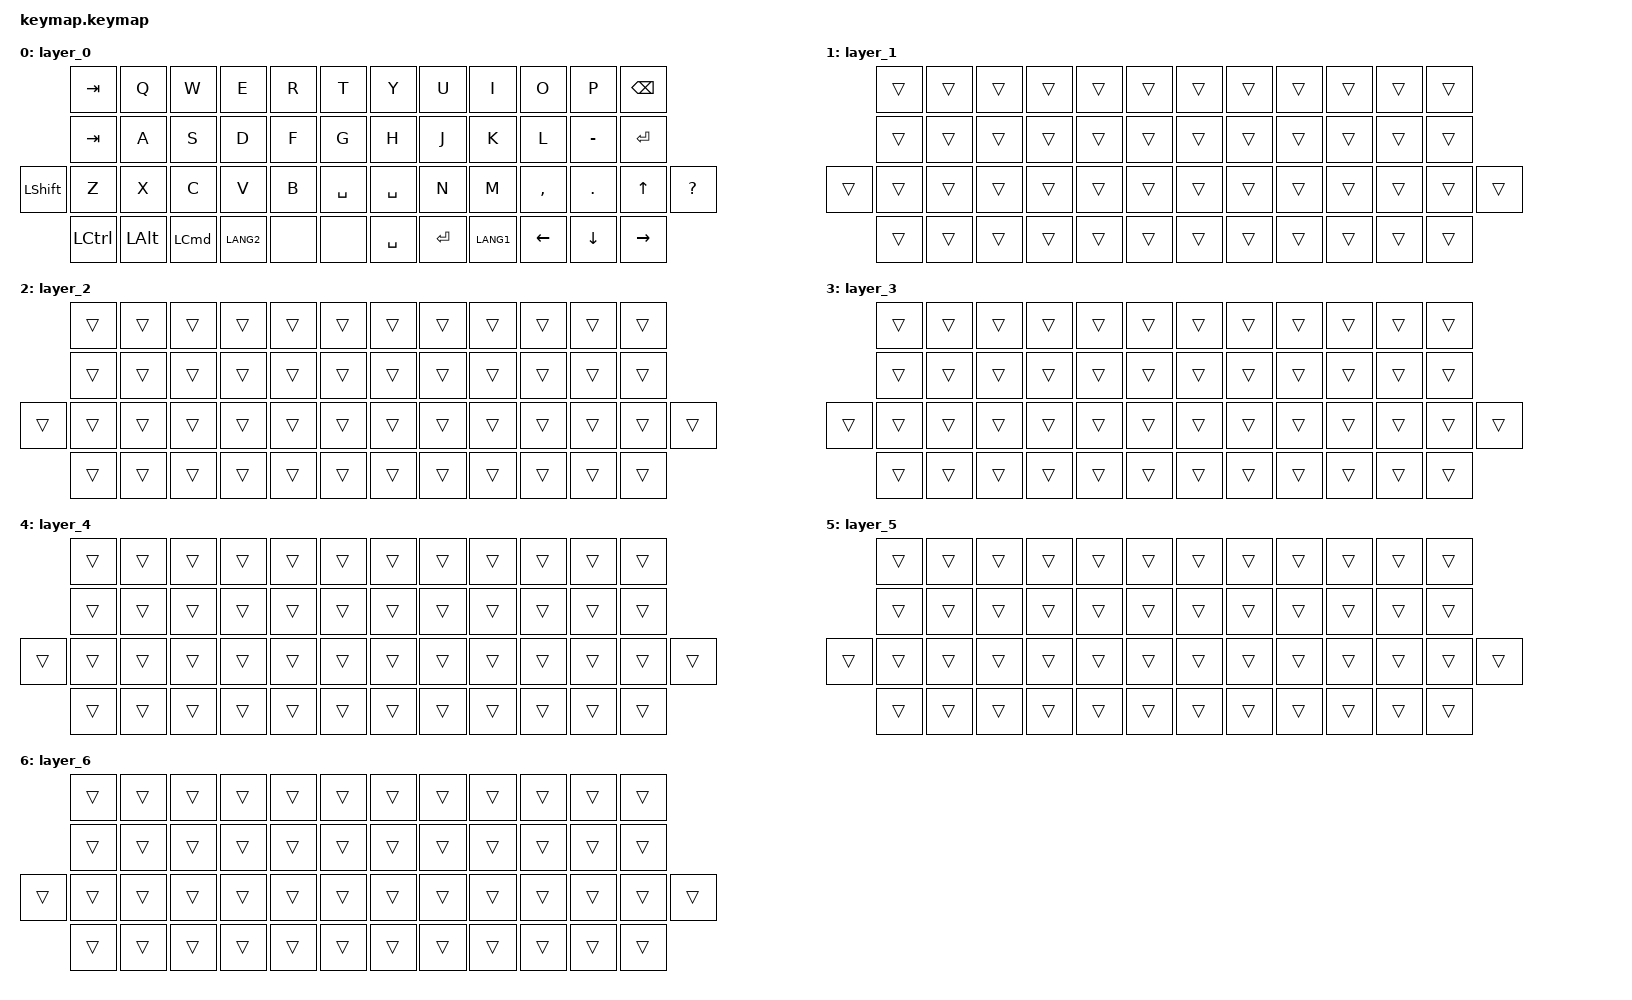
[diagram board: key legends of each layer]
#include <behaviors.dtsi>
#include <dt-bindings/zmk/keys.h>

/ {
    keymap {
        compatible = "zmk,keymap";
        layer_0 {
            bindings = <
&kp TAB  &kp Q  &kp W  &kp E  &kp R  &kp T  &kp Y  &kp U  &kp I  &kp O  &kp P  &kp BSPC
&kp TAB  &kp A  &kp S  &kp D  &kp F  &kp G  &kp H  &kp J  &kp K  &kp L  &kp MINUS  &kp ENTER
&kp LSHFT  &kp Z  &kp X  &kp C  &kp V  &kp B  &kp SPACE  &kp SPACE  &kp N  &kp M  &kp COMMA  &kp DOT  &kp UP_ARROW  &kp QUESTION
&kp LEFT_CONTROL  &kp LALT  &kp LEFT_COMMAND  &kp LANG2  &none  &none  &kp SPACE  &kp ENTER  &kp LANG1  &kp LEFT_ARROW  &kp DOWN_ARROW  &kp RIGHT_ARROW
                        >;
        };
        layer_1 {
            bindings = <&trans &trans &trans &trans &trans &trans &trans &trans &trans &trans &trans &trans &trans &trans &trans &trans &trans &trans &trans &trans &trans &trans &trans &trans &trans &trans &trans &trans &trans &trans &trans &trans &trans &trans &trans &trans &trans &trans &trans &trans &trans &trans &trans &trans &trans &trans &trans &trans &trans &trans>;
        };
        layer_2 {
            bindings = <&trans &trans &trans &trans &trans &trans &trans &trans &trans &trans &trans &trans &trans &trans &trans &trans &trans &trans &trans &trans &trans &trans &trans &trans &trans &trans &trans &trans &trans &trans &trans &trans &trans &trans &trans &trans &trans &trans &trans &trans &trans &trans &trans &trans &trans &trans &trans &trans &trans &trans>;
        };
        layer_3 {
            bindings = <&trans &trans &trans &trans &trans &trans &trans &trans &trans &trans &trans &trans &trans &trans &trans &trans &trans &trans &trans &trans &trans &trans &trans &trans &trans &trans &trans &trans &trans &trans &trans &trans &trans &trans &trans &trans &trans &trans &trans &trans &trans &trans &trans &trans &trans &trans &trans &trans &trans &trans>;
        };
        layer_4 {
            bindings = <&trans &trans &trans &trans &trans &trans &trans &trans &trans &trans &trans &trans &trans &trans &trans &trans &trans &trans &trans &trans &trans &trans &trans &trans &trans &trans &trans &trans &trans &trans &trans &trans &trans &trans &trans &trans &trans &trans &trans &trans &trans &trans &trans &trans &trans &trans &trans &trans &trans &trans>;
        };
        layer_5 {
            bindings = <&trans &trans &trans &trans &trans &trans &trans &trans &trans &trans &trans &trans &trans &trans &trans &trans &trans &trans &trans &trans &trans &trans &trans &trans &trans &trans &trans &trans &trans &trans &trans &trans &trans &trans &trans &trans &trans &trans &trans &trans &trans &trans &trans &trans &trans &trans &trans &trans &trans &trans>;
        };
        layer_6 {
            bindings = <&trans &trans &trans &trans &trans &trans &trans &trans &trans &trans &trans &trans &trans &trans &trans &trans &trans &trans &trans &trans &trans &trans &trans &trans &trans &trans &trans &trans &trans &trans &trans &trans &trans &trans &trans &trans &trans &trans &trans &trans &trans &trans &trans &trans &trans &trans &trans &trans &trans &trans>;
        };
    };
};
